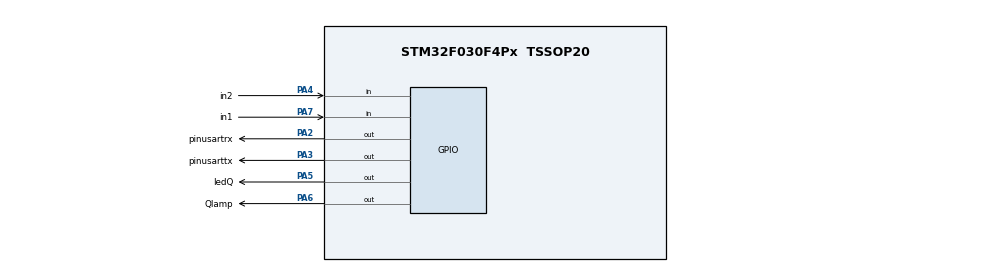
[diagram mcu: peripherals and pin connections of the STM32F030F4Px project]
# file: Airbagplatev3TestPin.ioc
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Mcu.Family=STM32F0
Mcu.Name=STM32F030F4Px
Mcu.Package=TSSOP20
PA13.Mode=Serial_Wire
PA13.Signal=SYS_SWDIO
PA14.Mode=Serial_Wire
PA14.Signal=SYS_SWCLK
PA2.GPIO_Label=pinusartrx
PA2.Signal=GPIO_Output
PA3.GPIO_Label=pinusarttx
PA3.Signal=GPIO_Output
PA4.GPIO_Label=in2
PA4.Signal=GPIO_Input
PA5.GPIO_Label=ledQ
PA5.Signal=GPIO_Output
PA6.GPIO_Label=Qlamp
PA6.Signal=GPIO_Output
PA7.GPIO_Label=in1
PA7.Signal=GPIO_Input
ProjectManager.HeapSize=0x200
ProjectManager.StackSize=0x400
ProjectManager.TargetToolchain=SW4STM32
board=custom

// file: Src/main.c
/* USER CODE BEGIN Header */
/**
  ******************************************************************************
  * @file           : main.c
  * @brief          : Main program body
  ******************************************************************************
  * @attention
  *
  * <h2><center>&copy; Copyright (c) 2019 STMicroelectronics.
  * All rights reserved.</center></h2>
  *
  * This software component is licensed by ST under BSD 3-Clause license,
  * the "License"; You may not use this file except in compliance with the
  * License. You may obtain a copy of the License at:
  *                        opensource.org/licenses/BSD-3-Clause
  *
  ******************************************************************************
  */
/* USER CODE END Header */

#include "main.h"

void SystemClock_Config(void);
static void MX_GPIO_Init(void);

int main(void)
{

  /* MCU Configuration--------------------------------------------------------*/

  /* Reset of all peripherals, Initializes the Flash interface and the Systick. */
  HAL_Init();

  /* Configure the system clock */
  SystemClock_Config();

  /* Initialize all configured peripherals */
  MX_GPIO_Init();

  /* Infinite loop */
  /* USER CODE BEGIN WHILE */
  while (1)
  {
	/*
	  HAL_GPIO_WritePin(GPIOA,ledQ_Pin,GPIO_PIN_SET);
	  HAL_GPIO_WritePin(GPIOA,Qlamp_Pin,GPIO_PIN_SET);
	  HAL_Delay(500);
	  HAL_GPIO_WritePin(GPIOA,ledQ_Pin,GPIO_PIN_RESET);
	  HAL_GPIO_WritePin(GPIOA,Qlamp_Pin,GPIO_PIN_RESET);
      HAL_Delay(500);
    */
      if(HAL_GPIO_ReadPin(GPIOA,in1_Pin)==1){
    	      HAL_GPIO_WritePin(GPIOA,pinusartrx_Pin,GPIO_PIN_SET);
    	 	  HAL_GPIO_WritePin(GPIOA,pinusarttx_Pin,GPIO_PIN_SET);
    	 	  HAL_Delay(500);
    	 	  HAL_GPIO_WritePin(GPIOA,pinusartrx_Pin,GPIO_PIN_RESET);
    	 	  HAL_GPIO_WritePin(GPIOA,pinusarttx_Pin,GPIO_PIN_RESET);
    	       HAL_Delay(500);
      }
      if(HAL_GPIO_ReadPin(GPIOA,in2_Pin)==1){
          	      HAL_GPIO_WritePin(GPIOA,pinusartrx_Pin,GPIO_PIN_SET);
          	 	  HAL_GPIO_WritePin(GPIOA,pinusarttx_Pin,GPIO_PIN_SET);
          	 	  HAL_Delay(500);
          	 	  HAL_GPIO_WritePin(GPIOA,pinusartrx_Pin,GPIO_PIN_RESET);
          	 	  HAL_GPIO_WritePin(GPIOA,pinusarttx_Pin,GPIO_PIN_RESET);
          	       HAL_Delay(500);
            }

    /* USER CODE END WHILE */

  }
}

void SystemClock_Config(void)
{
  RCC_OscInitTypeDef RCC_OscInitStruct = {0};
  RCC_ClkInitTypeDef RCC_ClkInitStruct = {0};

  /** Initializes the CPU, AHB and APB busses clocks
  */
  RCC_OscInitStruct.OscillatorType = RCC_OSCILLATORTYPE_HSI;
  RCC_OscInitStruct.HSIState = RCC_HSI_ON;
  RCC_OscInitStruct.HSICalibrationValue = RCC_HSICALIBRATION_DEFAULT;
  RCC_OscInitStruct.PLL.PLLState = RCC_PLL_NONE;
  if (HAL_RCC_OscConfig(&RCC_OscInitStruct) != HAL_OK)
  {
    Error_Handler();
  }
  /** Initializes the CPU, AHB and APB busses clocks
  */
  RCC_ClkInitStruct.ClockType = RCC_CLOCKTYPE_HCLK|RCC_CLOCKTYPE_SYSCLK
                              |RCC_CLOCKTYPE_PCLK1;
  RCC_ClkInitStruct.SYSCLKSource = RCC_SYSCLKSOURCE_HSI;
  RCC_ClkInitStruct.AHBCLKDivider = RCC_SYSCLK_DIV1;
  RCC_ClkInitStruct.APB1CLKDivider = RCC_HCLK_DIV1;

  if (HAL_RCC_ClockConfig(&RCC_ClkInitStruct, FLASH_LATENCY_0) != HAL_OK)
  {
    Error_Handler();
  }
}

static void MX_GPIO_Init(void)
{
  GPIO_InitTypeDef GPIO_InitStruct = {0};

  /* GPIO Ports Clock Enable */
  __HAL_RCC_GPIOA_CLK_ENABLE();

  /*Configure GPIO pin Output Level */
  HAL_GPIO_WritePin(GPIOA, pinusartrx_Pin|pinusarttx_Pin|ledQ_Pin|Qlamp_Pin, GPIO_PIN_RESET);

  /*Configure GPIO pins : pinusartrx_Pin pinusarttx_Pin ledQ_Pin Qlamp_Pin */
  GPIO_InitStruct.Pin = pinusartrx_Pin|pinusarttx_Pin|ledQ_Pin|Qlamp_Pin;
  GPIO_InitStruct.Mode = GPIO_MODE_OUTPUT_PP;
  GPIO_InitStruct.Pull = GPIO_NOPULL;
  GPIO_InitStruct.Speed = GPIO_SPEED_FREQ_LOW;
  HAL_GPIO_Init(GPIOA, &GPIO_InitStruct);

  /*Configure GPIO pins : in2_Pin in1_Pin */
  GPIO_InitStruct.Pin = in2_Pin|in1_Pin;
  GPIO_InitStruct.Mode = GPIO_MODE_INPUT;
  GPIO_InitStruct.Pull = GPIO_NOPULL;
  HAL_GPIO_Init(GPIOA, &GPIO_InitStruct);

}

void Error_Handler(void)
{
}

/************************ (C) COPYRIGHT STMicroelectronics *****END OF FILE****/
